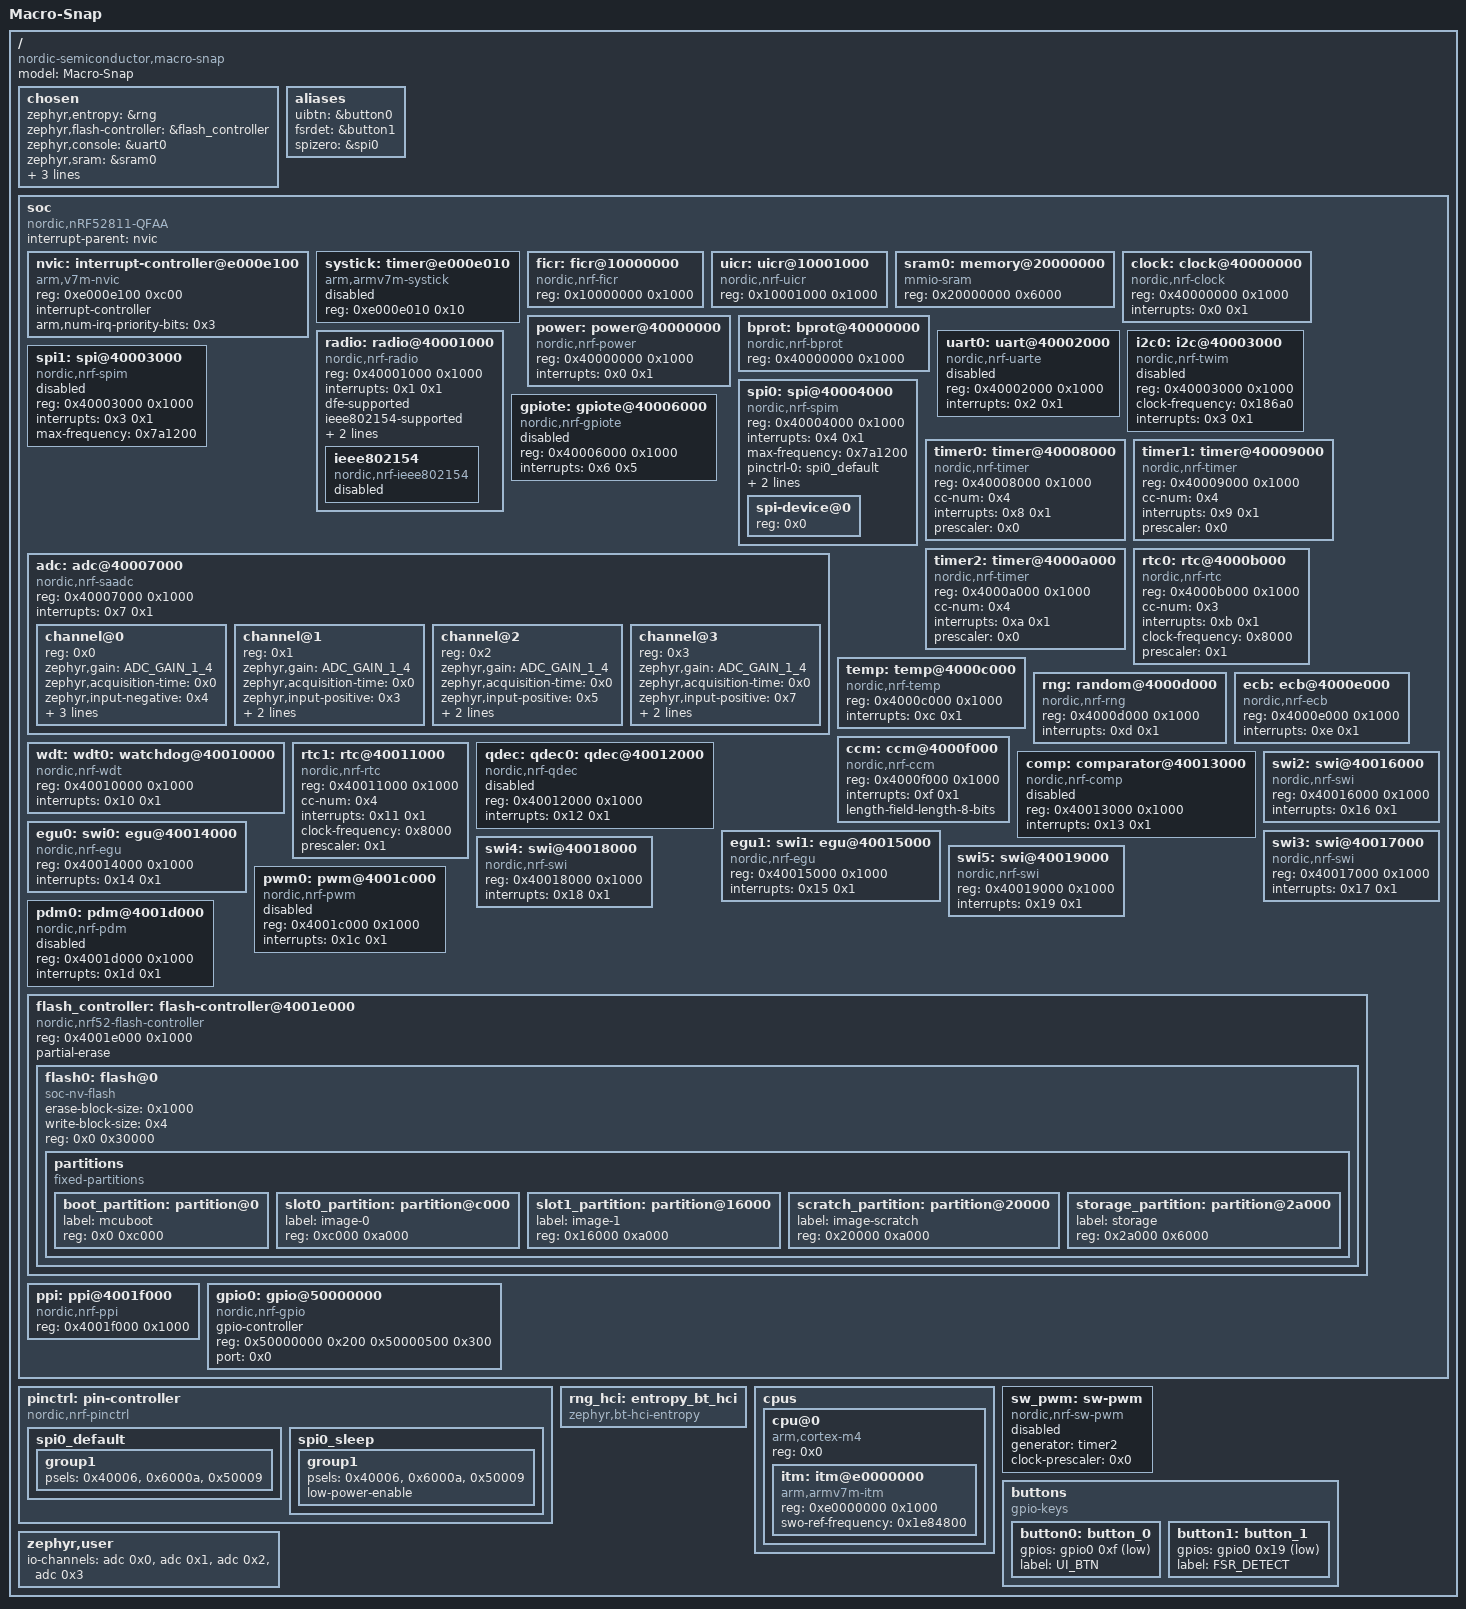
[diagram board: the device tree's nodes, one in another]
/dts-v1/;

/ {
	#address-cells = < 0x1 >;
	#size-cells = < 0x1 >;
	model = "Macro-Snap";
	compatible = "nordic-semiconductor,macro-snap";
	chosen {
		zephyr,entropy = &rng;
		zephyr,flash-controller = &flash_controller;
		zephyr,console = &uart0;
		zephyr,sram = &sram0;
		zephyr,flash = &flash0;
		zephyr,code-partition = &slot0_partition;
		zephyr,uart-mcumgr = &uart0;
	};
	aliases {
		uibtn = &button0;
		fsrdet = &button1;
		spizero = &spi0;
	};
	soc {
		#address-cells = < 0x1 >;
		#size-cells = < 0x1 >;
		compatible = "nordic,nRF52811-QFAA", "nordic,nRF52811", "nordic,nRF52", "simple-bus";
		interrupt-parent = < &nvic >;
		ranges;
		nvic: interrupt-controller@e000e100 {
			#address-cells = < 0x1 >;
			compatible = "arm,v7m-nvic";
			reg = < 0xe000e100 0xc00 >;
			interrupt-controller;
			#interrupt-cells = < 0x2 >;
			arm,num-irq-priority-bits = < 0x3 >;
			phandle = < 0x1 >;
		};
		systick: timer@e000e010 {
			compatible = "arm,armv7m-systick";
			reg = < 0xe000e010 0x10 >;
			status = "disabled";
		};
		ficr: ficr@10000000 {
			compatible = "nordic,nrf-ficr";
			reg = < 0x10000000 0x1000 >;
			status = "okay";
		};
		uicr: uicr@10001000 {
			compatible = "nordic,nrf-uicr";
			reg = < 0x10001000 0x1000 >;
			status = "okay";
		};
		sram0: memory@20000000 {
			compatible = "mmio-sram";
			reg = < 0x20000000 0x6000 >;
		};
		clock: clock@40000000 {
			compatible = "nordic,nrf-clock";
			reg = < 0x40000000 0x1000 >;
			interrupts = < 0x0 0x1 >;
			status = "okay";
		};
		power: power@40000000 {
			compatible = "nordic,nrf-power";
			reg = < 0x40000000 0x1000 >;
			interrupts = < 0x0 0x1 >;
			status = "okay";
		};
		bprot: bprot@40000000 {
			compatible = "nordic,nrf-bprot";
			reg = < 0x40000000 0x1000 >;
			status = "okay";
		};
		radio: radio@40001000 {
			compatible = "nordic,nrf-radio";
			reg = < 0x40001000 0x1000 >;
			interrupts = < 0x1 0x1 >;
			status = "okay";
			dfe-supported;
			ieee802154-supported;
			ble-2mbps-supported;
			ble-coded-phy-supported;
			ieee802154: ieee802154 {
				compatible = "nordic,nrf-ieee802154";
				status = "disabled";
			};
		};
		uart0: uart@40002000 {
			compatible = "nordic,nrf-uarte";
			reg = < 0x40002000 0x1000 >;
			interrupts = < 0x2 0x1 >;
			status = "disabled";
		};
		i2c0: i2c@40003000 {
			compatible = "nordic,nrf-twim";
			#address-cells = < 0x1 >;
			#size-cells = < 0x0 >;
			reg = < 0x40003000 0x1000 >;
			clock-frequency = < 0x186a0 >;
			interrupts = < 0x3 0x1 >;
			status = "disabled";
		};
		spi1: spi@40003000 {
			compatible = "nordic,nrf-spim";
			#address-cells = < 0x1 >;
			#size-cells = < 0x0 >;
			reg = < 0x40003000 0x1000 >;
			interrupts = < 0x3 0x1 >;
			max-frequency = < 0x7a1200 >;
			status = "disabled";
		};
		spi0: spi@40004000 {
			compatible = "nordic,nrf-spim";
			#address-cells = < 0x1 >;
			#size-cells = < 0x0 >;
			reg = < 0x40004000 0x1000 >;
			interrupts = < 0x4 0x1 >;
			max-frequency = < 0x7a1200 >;
			status = "okay";
			pinctrl-0 = < &spi0_default >;
			pinctrl-1 = < &spi0_sleep >;
			cs-gpios = < &gpio0 0x1 0x1 >;
			pinctrl-names = "default", "sleep";
			spi-device@0 {
				reg = < 0x0 >;
			};
		};
		gpiote: gpiote@40006000 {
			compatible = "nordic,nrf-gpiote";
			reg = < 0x40006000 0x1000 >;
			interrupts = < 0x6 0x5 >;
			status = "disabled";
		};
		adc: adc@40007000 {
			compatible = "nordic,nrf-saadc";
			reg = < 0x40007000 0x1000 >;
			interrupts = < 0x7 0x1 >;
			status = "okay";
			#io-channel-cells = < 0x1 >;
			#address-cells = < 0x1 >;
			#size-cells = < 0x0 >;
			phandle = < 0x6 >;
			channel@0 {
				reg = < 0x0 >;
				zephyr,gain = "ADC_GAIN_1_4";
				zephyr,acquisition-time = < 0x0 >;
				zephyr,input-negative = < 0x4 >;
				zephyr,input-positive = < 0x9 >;
				zephyr,reference = "ADC_REF_VDD_1_4";
				zephyr,resolution = < 0x8 >;
			};
			channel@1 {
				reg = < 0x1 >;
				zephyr,gain = "ADC_GAIN_1_4";
				zephyr,acquisition-time = < 0x0 >;
				zephyr,input-positive = < 0x3 >;
				zephyr,reference = "ADC_REF_VDD_1_4";
				zephyr,resolution = < 0x8 >;
			};
			channel@2 {
				reg = < 0x2 >;
				zephyr,gain = "ADC_GAIN_1_4";
				zephyr,acquisition-time = < 0x0 >;
				zephyr,input-positive = < 0x5 >;
				zephyr,reference = "ADC_REF_VDD_1_4";
				zephyr,resolution = < 0x8 >;
			};
			channel@3 {
				reg = < 0x3 >;
				zephyr,gain = "ADC_GAIN_1_4";
				zephyr,acquisition-time = < 0x0 >;
				zephyr,input-positive = < 0x7 >;
				zephyr,reference = "ADC_REF_VDD_1_4";
				zephyr,resolution = < 0x8 >;
			};
		};
		timer0: timer@40008000 {
			compatible = "nordic,nrf-timer";
			status = "okay";
			reg = < 0x40008000 0x1000 >;
			cc-num = < 0x4 >;
			interrupts = < 0x8 0x1 >;
			prescaler = < 0x0 >;
		};
		timer1: timer@40009000 {
			compatible = "nordic,nrf-timer";
			status = "okay";
			reg = < 0x40009000 0x1000 >;
			cc-num = < 0x4 >;
			interrupts = < 0x9 0x1 >;
			prescaler = < 0x0 >;
		};
		timer2: timer@4000a000 {
			compatible = "nordic,nrf-timer";
			status = "okay";
			reg = < 0x4000a000 0x1000 >;
			cc-num = < 0x4 >;
			interrupts = < 0xa 0x1 >;
			prescaler = < 0x0 >;
			phandle = < 0x5 >;
		};
		rtc0: rtc@4000b000 {
			compatible = "nordic,nrf-rtc";
			reg = < 0x4000b000 0x1000 >;
			cc-num = < 0x3 >;
			interrupts = < 0xb 0x1 >;
			status = "okay";
			clock-frequency = < 0x8000 >;
			prescaler = < 0x1 >;
		};
		temp: temp@4000c000 {
			compatible = "nordic,nrf-temp";
			reg = < 0x4000c000 0x1000 >;
			interrupts = < 0xc 0x1 >;
			status = "okay";
		};
		rng: random@4000d000 {
			compatible = "nordic,nrf-rng";
			reg = < 0x4000d000 0x1000 >;
			interrupts = < 0xd 0x1 >;
			status = "okay";
		};
		ecb: ecb@4000e000 {
			compatible = "nordic,nrf-ecb";
			reg = < 0x4000e000 0x1000 >;
			interrupts = < 0xe 0x1 >;
			status = "okay";
		};
		ccm: ccm@4000f000 {
			compatible = "nordic,nrf-ccm";
			reg = < 0x4000f000 0x1000 >;
			interrupts = < 0xf 0x1 >;
			length-field-length-8-bits;
			status = "okay";
		};
		wdt: wdt0: watchdog@40010000 {
			compatible = "nordic,nrf-wdt";
			reg = < 0x40010000 0x1000 >;
			interrupts = < 0x10 0x1 >;
			status = "okay";
		};
		rtc1: rtc@40011000 {
			compatible = "nordic,nrf-rtc";
			reg = < 0x40011000 0x1000 >;
			cc-num = < 0x4 >;
			interrupts = < 0x11 0x1 >;
			status = "okay";
			clock-frequency = < 0x8000 >;
			prescaler = < 0x1 >;
		};
		qdec: qdec0: qdec@40012000 {
			compatible = "nordic,nrf-qdec";
			reg = < 0x40012000 0x1000 >;
			interrupts = < 0x12 0x1 >;
			status = "disabled";
		};
		comp: comparator@40013000 {
			compatible = "nordic,nrf-comp";
			reg = < 0x40013000 0x1000 >;
			interrupts = < 0x13 0x1 >;
			status = "disabled";
			#io-channel-cells = < 0x1 >;
		};
		egu0: swi0: egu@40014000 {
			compatible = "nordic,nrf-egu", "nordic,nrf-swi";
			reg = < 0x40014000 0x1000 >;
			interrupts = < 0x14 0x1 >;
			status = "okay";
		};
		egu1: swi1: egu@40015000 {
			compatible = "nordic,nrf-egu", "nordic,nrf-swi";
			reg = < 0x40015000 0x1000 >;
			interrupts = < 0x15 0x1 >;
			status = "okay";
		};
		swi2: swi@40016000 {
			compatible = "nordic,nrf-swi";
			reg = < 0x40016000 0x1000 >;
			interrupts = < 0x16 0x1 >;
			status = "okay";
		};
		swi3: swi@40017000 {
			compatible = "nordic,nrf-swi";
			reg = < 0x40017000 0x1000 >;
			interrupts = < 0x17 0x1 >;
			status = "okay";
		};
		swi4: swi@40018000 {
			compatible = "nordic,nrf-swi";
			reg = < 0x40018000 0x1000 >;
			interrupts = < 0x18 0x1 >;
			status = "okay";
		};
		swi5: swi@40019000 {
			compatible = "nordic,nrf-swi";
			reg = < 0x40019000 0x1000 >;
			interrupts = < 0x19 0x1 >;
			status = "okay";
		};
		pwm0: pwm@4001c000 {
			compatible = "nordic,nrf-pwm";
			reg = < 0x4001c000 0x1000 >;
			interrupts = < 0x1c 0x1 >;
			status = "disabled";
			#pwm-cells = < 0x3 >;
		};
		pdm0: pdm@4001d000 {
			compatible = "nordic,nrf-pdm";
			reg = < 0x4001d000 0x1000 >;
			interrupts = < 0x1d 0x1 >;
			status = "disabled";
		};
		flash_controller: flash-controller@4001e000 {
			compatible = "nordic,nrf52-flash-controller";
			reg = < 0x4001e000 0x1000 >;
			partial-erase;
			#address-cells = < 0x1 >;
			#size-cells = < 0x1 >;
			flash0: flash@0 {
				compatible = "soc-nv-flash";
				erase-block-size = < 0x1000 >;
				write-block-size = < 0x4 >;
				reg = < 0x0 0x30000 >;
				partitions {
					compatible = "fixed-partitions";
					#address-cells = < 0x1 >;
					#size-cells = < 0x1 >;
					boot_partition: partition@0 {
						label = "mcuboot";
						reg = < 0x0 0xc000 >;
					};
					slot0_partition: partition@c000 {
						label = "image-0";
						reg = < 0xc000 0xa000 >;
					};
					slot1_partition: partition@16000 {
						label = "image-1";
						reg = < 0x16000 0xa000 >;
					};
					scratch_partition: partition@20000 {
						label = "image-scratch";
						reg = < 0x20000 0xa000 >;
					};
					storage_partition: partition@2a000 {
						label = "storage";
						reg = < 0x2a000 0x6000 >;
					};
				};
			};
		};
		ppi: ppi@4001f000 {
			compatible = "nordic,nrf-ppi";
			reg = < 0x4001f000 0x1000 >;
			status = "okay";
		};
		gpio0: gpio@50000000 {
			compatible = "nordic,nrf-gpio";
			gpio-controller;
			reg = < 0x50000000 0x200 0x50000500 0x300 >;
			#gpio-cells = < 0x2 >;
			status = "okay";
			port = < 0x0 >;
			phandle = < 0x4 >;
		};
	};
	pinctrl: pin-controller {
		compatible = "nordic,nrf-pinctrl";
		spi0_default: spi0_default {
			phandle = < 0x2 >;
			group1 {
				psels = < 0x40006 >, < 0x6000a >, < 0x50009 >;
			};
		};
		spi0_sleep: spi0_sleep {
			phandle = < 0x3 >;
			group1 {
				psels = < 0x40006 >, < 0x6000a >, < 0x50009 >;
				low-power-enable;
			};
		};
	};
	rng_hci: entropy_bt_hci {
		compatible = "zephyr,bt-hci-entropy";
		status = "okay";
	};
	cpus {
		#address-cells = < 0x1 >;
		#size-cells = < 0x0 >;
		cpu@0 {
			device_type = "cpu";
			compatible = "arm,cortex-m4";
			reg = < 0x0 >;
			#address-cells = < 0x1 >;
			#size-cells = < 0x1 >;
			itm: itm@e0000000 {
				compatible = "arm,armv7m-itm";
				reg = < 0xe0000000 0x1000 >;
				swo-ref-frequency = < 0x1e84800 >;
			};
		};
	};
	sw_pwm: sw-pwm {
		compatible = "nordic,nrf-sw-pwm";
		status = "disabled";
		generator = < &timer2 >;
		clock-prescaler = < 0x0 >;
		#pwm-cells = < 0x3 >;
	};
	buttons {
		compatible = "gpio-keys";
		button0: button_0 {
			gpios = < &gpio0 0xf 0x11 >;
			label = "UI_BTN";
		};
		button1: button_1 {
			gpios = < &gpio0 0x19 0x11 >;
			label = "FSR_DETECT";
		};
	};
	zephyr,user {
		io-channels = < &adc 0x0 >, < &adc 0x1 >, < &adc 0x2 >, < &adc 0x3 >;
		io-channel-names = "VBAT", "FSR1", "FSR2", "FSR3";
	};
};
